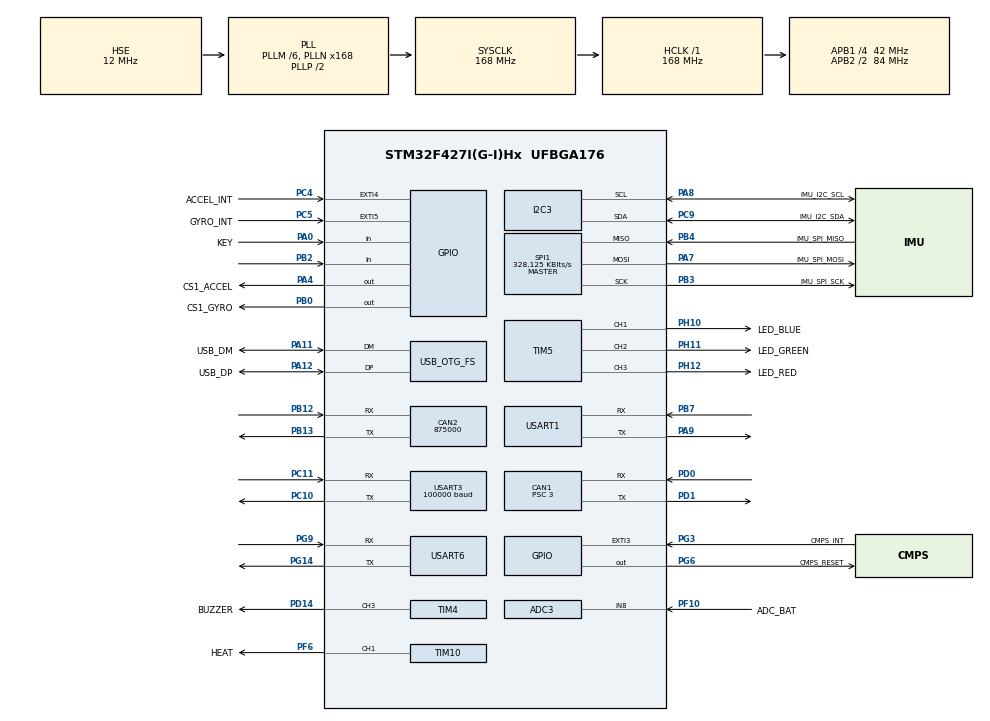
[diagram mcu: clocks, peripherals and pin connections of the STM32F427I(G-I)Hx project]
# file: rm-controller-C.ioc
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ADC3.Channel-0\#ChannelRegularConversion=ADC_CHANNEL_8
ADC3.NbrOfConversionFlag=1
ADC3.Rank-0\#ChannelRegularConversion=1
ADC3.SamplingTime-0\#ChannelRegularConversion=ADC_SAMPLETIME_3CYCLES
CAN1.BS1=CAN_BS1_10TQ
CAN1.BS2=CAN_BS2_3TQ
CAN1.CalculateBaudRate=1000000
CAN1.CalculateTimeBit=1000
CAN1.CalculateTimeQuantum=71.42857142857143
CAN1.Prescaler=3
CAN2.CalculateBaudRate=875000
CAN2.CalculateTimeBit=1142
CAN2.CalculateTimeQuantum=380.95238095238096
Dma.Request0=USART3_RX
Dma.Request1=USART1_RX
Dma.Request2=USART1_TX
Dma.Request3=SPI1_RX
Dma.Request4=SPI1_TX
Dma.Request5=USART6_RX
Dma.Request6=USART6_TX
Dma.SPI1_RX.3.Direction=DMA_PERIPH_TO_MEMORY
Dma.SPI1_RX.3.FIFOMode=DMA_FIFOMODE_DISABLE
Dma.SPI1_RX.3.Instance=DMA2_Stream0
Dma.SPI1_RX.3.MemDataAlignment=DMA_MDATAALIGN_BYTE
Dma.SPI1_RX.3.MemInc=DMA_MINC_ENABLE
Dma.SPI1_RX.3.Mode=DMA_NORMAL
Dma.SPI1_RX.3.PeriphDataAlignment=DMA_PDATAALIGN_BYTE
Dma.SPI1_RX.3.PeriphInc=DMA_PINC_DISABLE
Dma.SPI1_RX.3.Priority=DMA_PRIORITY_VERY_HIGH
Dma.SPI1_TX.4.Direction=DMA_MEMORY_TO_PERIPH
Dma.SPI1_TX.4.FIFOMode=DMA_FIFOMODE_DISABLE
Dma.SPI1_TX.4.Instance=DMA2_Stream3
Dma.SPI1_TX.4.MemDataAlignment=DMA_MDATAALIGN_BYTE
Dma.SPI1_TX.4.MemInc=DMA_MINC_ENABLE
Dma.SPI1_TX.4.Mode=DMA_NORMAL
Dma.SPI1_TX.4.PeriphDataAlignment=DMA_PDATAALIGN_BYTE
Dma.SPI1_TX.4.PeriphInc=DMA_PINC_DISABLE
Dma.SPI1_TX.4.Priority=DMA_PRIORITY_MEDIUM
Dma.USART1_RX.1.Direction=DMA_PERIPH_TO_MEMORY
Dma.USART1_RX.1.FIFOMode=DMA_FIFOMODE_DISABLE
Dma.USART1_RX.1.Instance=DMA2_Stream2
Dma.USART1_RX.1.MemDataAlignment=DMA_MDATAALIGN_BYTE
Dma.USART1_RX.1.MemInc=DMA_MINC_ENABLE
Dma.USART1_RX.1.Mode=DMA_CIRCULAR
Dma.USART1_RX.1.PeriphDataAlignment=DMA_PDATAALIGN_BYTE
Dma.USART1_RX.1.PeriphInc=DMA_PINC_DISABLE
Dma.USART1_RX.1.Priority=DMA_PRIORITY_LOW
Dma.USART1_TX.2.Direction=DMA_MEMORY_TO_PERIPH
Dma.USART1_TX.2.FIFOMode=DMA_FIFOMODE_DISABLE
Dma.USART1_TX.2.Instance=DMA2_Stream7
Dma.USART1_TX.2.MemDataAlignment=DMA_MDATAALIGN_BYTE
Dma.USART1_TX.2.MemInc=DMA_MINC_ENABLE
Dma.USART1_TX.2.Mode=DMA_CIRCULAR
Dma.USART1_TX.2.PeriphDataAlignment=DMA_PDATAALIGN_BYTE
Dma.USART1_TX.2.PeriphInc=DMA_PINC_DISABLE
Dma.USART1_TX.2.Priority=DMA_PRIORITY_LOW
Dma.USART3_RX.0.Direction=DMA_PERIPH_TO_MEMORY
Dma.USART3_RX.0.FIFOMode=DMA_FIFOMODE_DISABLE
Dma.USART3_RX.0.Instance=DMA1_Stream1
Dma.USART3_RX.0.MemDataAlignment=DMA_MDATAALIGN_BYTE
Dma.USART3_RX.0.MemInc=DMA_MINC_ENABLE
Dma.USART3_RX.0.Mode=DMA_CIRCULAR
Dma.USART3_RX.0.PeriphDataAlignment=DMA_PDATAALIGN_BYTE
Dma.USART3_RX.0.PeriphInc=DMA_PINC_DISABLE
Dma.USART3_RX.0.Priority=DMA_PRIORITY_VERY_HIGH
Dma.USART6_RX.5.Direction=DMA_PERIPH_TO_MEMORY
Dma.USART6_RX.5.FIFOMode=DMA_FIFOMODE_DISABLE
Dma.USART6_RX.5.Instance=DMA2_Stream1
Dma.USART6_RX.5.MemDataAlignment=DMA_MDATAALIGN_BYTE
Dma.USART6_RX.5.MemInc=DMA_MINC_ENABLE
Dma.USART6_RX.5.Mode=DMA_CIRCULAR
Dma.USART6_RX.5.PeriphDataAlignment=DMA_PDATAALIGN_BYTE
Dma.USART6_RX.5.PeriphInc=DMA_PINC_DISABLE
Dma.USART6_RX.5.Priority=DMA_PRIORITY_LOW
Dma.USART6_TX.6.Direction=DMA_MEMORY_TO_PERIPH
Dma.USART6_TX.6.FIFOMode=DMA_FIFOMODE_DISABLE
Dma.USART6_TX.6.Instance=DMA2_Stream6
Dma.USART6_TX.6.MemDataAlignment=DMA_MDATAALIGN_BYTE
Dma.USART6_TX.6.MemInc=DMA_MINC_ENABLE
Dma.USART6_TX.6.Mode=DMA_CIRCULAR
Dma.USART6_TX.6.PeriphDataAlignment=DMA_PDATAALIGN_BYTE
Dma.USART6_TX.6.PeriphInc=DMA_PINC_DISABLE
Dma.USART6_TX.6.Priority=DMA_PRIORITY_LOW
FREERTOS.Tasks01=default_task,24,300,defaultTask,As weak,NULL,Dynamic,NULL,NULL
FREERTOS.configENABLE_FPU=1
FREERTOS.configMINIMAL_STACK_SIZE=300
FREERTOS.configTOTAL_HEAP_SIZE=60000
FREERTOS.configUSE_POSIX_ERRNO=1
I2C3.I2C_Mode=I2C_Fast
Mcu.Family=STM32F4
Mcu.Name=STM32F427I(G-I)Hx
Mcu.Package=UFBGA176
NVIC.CAN1_RX0_IRQn=true\:5\:0\:false\:false\:true\:true\:true\:true\:true
NVIC.DMA1_Stream1_IRQn=true\:5\:0\:false\:false\:true\:true\:false\:true\:true
NVIC.DMA2_Stream0_IRQn=true\:5\:0\:false\:false\:true\:true\:false\:true\:true
NVIC.DMA2_Stream1_IRQn=true\:5\:0\:false\:false\:true\:true\:false\:true\:true
NVIC.DMA2_Stream2_IRQn=true\:5\:0\:false\:false\:true\:true\:false\:true\:true
NVIC.DMA2_Stream3_IRQn=true\:5\:0\:false\:false\:true\:true\:false\:true\:true
NVIC.DMA2_Stream6_IRQn=true\:5\:0\:false\:false\:true\:true\:false\:true\:true
NVIC.DMA2_Stream7_IRQn=true\:5\:0\:false\:false\:true\:true\:false\:true\:true
NVIC.EXTI3_IRQn=true\:5\:0\:false\:false\:true\:true\:true\:true\:true
NVIC.EXTI4_IRQn=true\:5\:0\:false\:false\:true\:true\:true\:true\:true
NVIC.EXTI9_5_IRQn=true\:5\:0\:false\:false\:true\:true\:true\:true\:true
NVIC.OTG_FS_IRQn=true\:10\:0\:true\:false\:true\:true\:true\:true\:true
NVIC.PriorityGroup=NVIC_PRIORITYGROUP_4
NVIC.TIM1_UP_TIM10_IRQn=true\:15\:0\:true\:false\:true\:false\:true\:true\:true
NVIC.TimeBase=TIM1_UP_TIM10_IRQn
NVIC.TimeBaseIP=TIM1
NVIC.USART1_IRQn=true\:5\:0\:false\:false\:true\:true\:true\:true\:true
NVIC.USART3_IRQn=true\:5\:0\:false\:false\:true\:true\:true\:true\:true
PA0/WKUP.GPIO_Label=KEY
PA0/WKUP.Signal=GPIO_Input
PA11.GPIO_Label=USB_DM
PA11.Mode=Device_Only
PA11.Signal=USB_OTG_FS_DM
PA12.GPIO_Label=USB_DP
PA12.Mode=Device_Only
PA12.Signal=USB_OTG_FS_DP
PA13.Mode=Serial_Wire
PA13.Signal=SYS_JTMS-SWDIO
PA14.Mode=Serial_Wire
PA14.Signal=SYS_JTCK-SWCLK
PA4.GPIO_Label=CS1_ACCEL
PA4.GPIO_PuPd=GPIO_PULLUP
PA4.Signal=GPIO_Output
PA7.GPIO_Label=IMU_SPI_MOSI
PA7.Mode=Full_Duplex_Master
PA7.Signal=SPI1_MOSI
PA8.GPIO_Label=IMU_I2C_SCL
PA8.Mode=I2C
PA8.Signal=I2C3_SCL
PA9.Mode=Asynchronous
PA9.Signal=USART1_TX
PB0.GPIO_Label=CS1_GYRO
PB0.GPIO_PuPd=GPIO_PULLUP
PB0.Signal=GPIO_Output
PB12.Signal=SharedStack_PB12
PB12.Stacked=true
PB13.Signal=SharedStack_PB13
PB13.Stacked=true
PB14.Signal=SPI2_MISO
PB15.Signal=SPI2_MOSI
PB2/BOOT1.Signal=GPIO_Input
PB3.GPIO_Label=IMU_SPI_SCK
PB3.Mode=Full_Duplex_Master
PB3.Signal=SPI1_SCK
PB4.GPIO_Label=IMU_SPI_MISO
PB4.Mode=Full_Duplex_Master
PB4.Signal=SPI1_MISO
PB7.Mode=Asynchronous
PB7.Signal=USART1_RX
PC10.GPIO_ModeDefaultPP=GPIO_MODE_AF_PP
PC10.Mode=Asynchronous
PC10.Signal=USART3_TX
PC11.Mode=Asynchronous
PC11.Signal=USART3_RX
PC4.GPIO_Label=ACCEL_INT
PC4.GPIO_PuPd=GPIO_PULLUP
PC4.Signal=GPXTI4
PC5.GPIO_Label=GYRO_INT
PC5.GPIO_PuPd=GPIO_PULLUP
PC5.Signal=GPXTI5
PC6.Signal=S_TIM8_CH1
PC9.GPIO_Label=IMU_I2C_SDA
PC9.Mode=I2C
PC9.Signal=I2C3_SDA
PD0.Mode=CAN_Activate
PD0.Signal=CAN1_RX
PD1.Mode=CAN_Activate
PD1.Signal=CAN1_TX
PD14.GPIO_Label=BUZZER
PD14.Signal=S_TIM4_CH3
PE11.Signal=S_TIM1_CH2
PE13.Signal=S_TIM1_CH3
PE14.Signal=S_TIM1_CH4
PE9.Signal=S_TIM1_CH1
PF0.Signal=I2C2_SDA
PF1.Signal=I2C2_SCL
PF10.GPIO_Label=ADC_BAT
PF10.Mode=IN8
PF10.Signal=ADC3_IN8
PF6.GPIO_Label=HEAT
PF6.Signal=S_TIM10_CH1
PG14.Mode=Asynchronous
PG14.Signal=USART6_TX
PG3.GPIO_Label=CMPS_INT
PG3.GPIO_ModeDefaultEXTI=GPIO_MODE_IT_FALLING
PG3.GPIO_PuPd=GPIO_PULLUP
PG3.Signal=GPXTI3
PG6.GPIO_Label=CMPS_RESET
PG6.GPIO_PuPd=GPIO_PULLUP
PG6.Signal=GPIO_Output
PG9.Mode=Asynchronous
PG9.Signal=USART6_RX
PH0/OSC_IN.Mode=HSE-External-Oscillator
PH0/OSC_IN.Signal=RCC_OSC_IN
PH1/OSC_OUT.Mode=HSE-External-Oscillator
PH1/OSC_OUT.Signal=RCC_OSC_OUT
PH10.GPIO_Label=LED_BLUE
PH10.Signal=S_TIM5_CH1
PH11.GPIO_Label=LED_GREEN
PH11.Signal=S_TIM5_CH2
PH12.GPIO_Label=LED_RED
PH12.Signal=S_TIM5_CH3
PI6.Signal=S_TIM8_CH2
PI7.Signal=S_TIM8_CH3
ProjectManager.HeapSize=0x1000
ProjectManager.StackSize=0x1000
ProjectManager.TargetToolchain=Makefile
RCC.48MHZClocksFreq_Value=48000000
RCC.AHBFreq_Value=168000000
RCC.APB1CLKDivider=RCC_HCLK_DIV4
RCC.APB1Freq_Value=42000000
RCC.APB1TimFreq_Value=84000000
RCC.APB2CLKDivider=RCC_HCLK_DIV2
RCC.APB2Freq_Value=84000000
RCC.APB2TimFreq_Value=168000000
RCC.CortexFreq_Value=168000000
RCC.HCLKFreq_Value=168000000
RCC.HSE_VALUE=12000000
RCC.HSI_VALUE=16000000
RCC.LSE_VALUE=32768
RCC.PLLM=6
RCC.PLLMUL=RCC_PLL_MUL9
RCC.PLLN=168
RCC.PLLQ=7
RCC.PRESCALERUSB=RCC_USBCLKSOURCE_PLL_DIV1_5
RCC.SYSCLKFreq_VALUE=168000000
RCC.SYSCLKSource=RCC_SYSCLKSOURCE_PLLCLK
RCC.SYSCLKSourceVirtual=RCC_SYSCLKSOURCE_PLLCLK
RCC.USBFreq_Value=48000000
RCC.VCOOutputFreq_Value=336000000
SH.S_TIM10_CH1.0=TIM10_CH1,PWM Generation1 CH1
SH.S_TIM1_CH1.0=TIM1_CH1
SH.S_TIM1_CH2.0=TIM1_CH2
SH.S_TIM1_CH3.0=TIM1_CH3
SH.S_TIM1_CH4.0=TIM1_CH4
SH.S_TIM4_CH3.0=TIM4_CH3,PWM Generation3 CH3
SH.S_TIM5_CH1.0=TIM5_CH1,PWM Generation1 CH1
SH.S_TIM5_CH2.0=TIM5_CH2,PWM Generation2 CH2
SH.S_TIM5_CH3.0=TIM5_CH3,PWM Generation3 CH3
SH.S_TIM8_CH1.0=TIM8_CH1
SH.S_TIM8_CH2.0=TIM8_CH2
SH.S_TIM8_CH3.0=TIM8_CH3
SH.SharedStack_PB12.0=SPI2_NSS
SH.SharedStack_PB12.1=CAN2_RX,CAN_Activate
SH.SharedStack_PB13.0=SPI2_SCK
SH.SharedStack_PB13.1=CAN2_TX,CAN_Activate
SPI1.BaudRatePrescaler=SPI_BAUDRATEPRESCALER_256
SPI1.CLKPhase=SPI_PHASE_2EDGE
SPI1.CLKPolarity=SPI_POLARITY_HIGH
SPI1.CalculateBaudRate=328.125 KBits/s
SPI1.Direction=SPI_DIRECTION_2LINES
SPI1.Mode=SPI_MODE_MASTER
SPI1.VirtualType=VM_MASTER
TIM10.Channel=TIM_CHANNEL_1
TIM10.Period=5000 - 1
TIM4.Channel-PWM\ Generation3\ CH3=TIM_CHANNEL_3
TIM4.Period=2999
TIM4.Prescaler=35
TIM5.Channel-PWM\ Generation1\ CH1=TIM_CHANNEL_1
TIM5.Channel-PWM\ Generation2\ CH2=TIM_CHANNEL_2
TIM5.Channel-PWM\ Generation3\ CH3=TIM_CHANNEL_3
USART1.VirtualMode=VM_ASYNC
USART3.BaudRate=100000
USART3.Mode=MODE_RX
USART3.Parity=PARITY_EVEN
USART3.VirtualMode=VM_ASYNC
USART6.VirtualMode=VM_ASYNC
USB_DEVICE.CLASS_NAME_FS=CDC
USB_DEVICE.USBD_DEBUG_LEVEL-CDC_FS=3
USB_DEVICE.VirtualMode-CDC_FS=Cdc
USB_DEVICE.VirtualModeFS=Cdc_FS
USB_OTG_FS.VirtualMode=Device_Only
VP_FREERTOS_VS_CMSIS_V2.Mode=CMSIS_V2
VP_SYS_VS_tim1.Mode=TIM1
VP_TIM10_VS_ClockSourceINT.Mode=Enable_Timer
VP_USB_DEVICE_VS_USB_DEVICE_CDC_FS.Mode=CDC_FS
board=Robomaster-Development-C

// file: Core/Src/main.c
/* USER CODE BEGIN Header */
/**
 ******************************************************************************
 * @file           : main.c
 * @brief          : Main program body
 ******************************************************************************
 * @attention
  *
  * Copyright (c) 2022 STMicroelectronics.
  * All rights reserved.
  *
  * This software is licensed under terms that can be found in the LICENSE file
  * in the root directory of this software component.
  * If no LICENSE file comes with this software, it is provided AS-IS.
  *
 ******************************************************************************
 */
/* USER CODE END Header */
#include "main.h"
#include "cmsis_os.h"
#include "adc.h"
#include "can.h"
#include "dma.h"
#include "i2c.h"
#include "spi.h"
#include "tim.h"
#include "usart.h"
#include "usb_device.h"
#include "gpio.h"

/* USER CODE BEGIN Includes */
#include "init.h"
/* USER CODE END Includes */

void SystemClock_Config(void);
void MX_FREERTOS_Init(void);

int main(void)
{

  /* MCU Configuration--------------------------------------------------------*/

  /* Reset of all peripherals, Initializes the Flash interface and the Systick. */
  HAL_Init();

  /* Configure the system clock */
  SystemClock_Config();

  /* Initialize all configured peripherals */
  MX_GPIO_Init();
  MX_DMA_Init();
  MX_ADC3_Init();
  MX_CAN1_Init();
  MX_CAN2_Init();
  MX_I2C3_Init();
  MX_SPI1_Init();
  MX_TIM4_Init();
  MX_TIM5_Init();
  MX_TIM10_Init();
  MX_USART1_UART_Init();
  MX_USART3_UART_Init();
  MX_USART6_UART_Init();
  /* USER CODE BEGIN 2 */
  userCodeInit();

  /* USER CODE END 2 */

  /* Init scheduler */
  osKernelInitialize();  /* Call init function for freertos objects (in freertos.c) */
  MX_FREERTOS_Init();

  /* Start scheduler */
  osKernelStart();

  /* We should never get here as control is now taken by the scheduler */
  /* Infinite loop */
  while (1)
  {

  }
}

void SystemClock_Config(void)
{
  RCC_OscInitTypeDef RCC_OscInitStruct = {0};
  RCC_ClkInitTypeDef RCC_ClkInitStruct = {0};

  /** Configure the main internal regulator output voltage
  */
  __HAL_RCC_PWR_CLK_ENABLE();
  __HAL_PWR_VOLTAGESCALING_CONFIG(PWR_REGULATOR_VOLTAGE_SCALE1);

  /** Initializes the RCC Oscillators according to the specified parameters
  * in the RCC_OscInitTypeDef structure.
  */
  RCC_OscInitStruct.OscillatorType = RCC_OSCILLATORTYPE_HSE;
  RCC_OscInitStruct.HSEState = RCC_HSE_ON;
  RCC_OscInitStruct.PLL.PLLState = RCC_PLL_ON;
  RCC_OscInitStruct.PLL.PLLSource = RCC_PLLSOURCE_HSE;
  RCC_OscInitStruct.PLL.PLLM = 6;
  RCC_OscInitStruct.PLL.PLLN = 168;
  RCC_OscInitStruct.PLL.PLLP = RCC_PLLP_DIV2;
  RCC_OscInitStruct.PLL.PLLQ = 7;
  if (HAL_RCC_OscConfig(&RCC_OscInitStruct) != HAL_OK)
  {
    Error_Handler();
  }

  /** Initializes the CPU, AHB and APB buses clocks
  */
  RCC_ClkInitStruct.ClockType = RCC_CLOCKTYPE_HCLK|RCC_CLOCKTYPE_SYSCLK
                              |RCC_CLOCKTYPE_PCLK1|RCC_CLOCKTYPE_PCLK2;
  RCC_ClkInitStruct.SYSCLKSource = RCC_SYSCLKSOURCE_PLLCLK;
  RCC_ClkInitStruct.AHBCLKDivider = RCC_SYSCLK_DIV1;
  RCC_ClkInitStruct.APB1CLKDivider = RCC_HCLK_DIV4;
  RCC_ClkInitStruct.APB2CLKDivider = RCC_HCLK_DIV2;

  if (HAL_RCC_ClockConfig(&RCC_ClkInitStruct, FLASH_LATENCY_5) != HAL_OK)
  {
    Error_Handler();
  }
}

void HAL_TIM_PeriodElapsedCallback(TIM_HandleTypeDef *htim)
{
  if (htim->Instance == TIM1) {
    HAL_IncTick();
  }
}

void Error_Handler(void)
{
  __disable_irq();
  while (1)
  {
  }
}

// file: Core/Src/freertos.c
/* USER CODE BEGIN Header */
/**
  ******************************************************************************
  * File Name          : freertos.c
  * Description        : Code for freertos applications
  ******************************************************************************
  * @attention
  *
  * <h2><center>&copy; Copyright (c) 2021 STMicroelectronics.
  * All rights reserved.</center></h2>
  *
  * This software component is licensed by ST under Ultimate Liberty license
  * SLA0044, the "License"; You may not use this file except in compliance with
  * the License. You may obtain a copy of the License at:
  *                             www.st.com/SLA0044
  *
  ******************************************************************************
  */
/* USER CODE END Header */

#include "FreeRTOS.h"
#include "task.h"
#include "main.h"
#include "cmsis_os.h"

/* Definitions for default_task */
osThreadId_t default_taskHandle;
const osThreadAttr_t default_task_attributes = {
  .name = "default_task",
  .stack_size = 300 * 4,
  .priority = (osPriority_t) osPriorityNormal,
};

void defaultTask(void *argument);

extern void MX_USB_DEVICE_Init(void);
void MX_FREERTOS_Init(void); /* (MISRA C 2004 rule 8.1) */

void MX_FREERTOS_Init(void) {

  /* Create the thread(s) */
  /* creation of default_task */
  default_taskHandle = osThreadNew(defaultTask, NULL, &default_task_attributes);

}

__weak void defaultTask(void *argument)
{
  /* init code for USB_DEVICE */
  MX_USB_DEVICE_Init();
  for(;;)
  {
    osDelay(1);
  }
}
